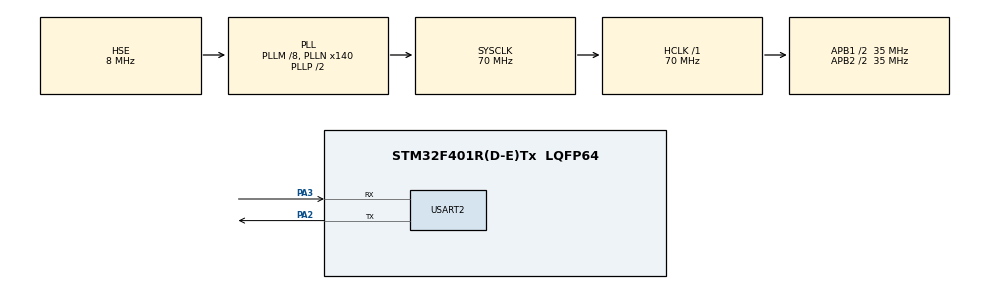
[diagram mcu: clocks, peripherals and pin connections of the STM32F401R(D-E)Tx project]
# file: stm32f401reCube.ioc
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Mcu.Family=STM32F4
Mcu.Name=STM32F401R(D-E)Tx
Mcu.Package=LQFP64
NVIC.PriorityGroup=NVIC_PRIORITYGROUP_4
NVIC.USART2_IRQn=true\:0\:0\:false\:false\:true\:true\:true
PA13.Mode=Serial_Wire
PA13.Signal=SYS_JTMS-SWDIO
PA14.Mode=Serial_Wire
PA14.Signal=SYS_JTCK-SWCLK
PA2.Mode=Asynchronous
PA2.Signal=USART2_TX
PA3.Mode=Asynchronous
PA3.Signal=USART2_RX
PH0\ -\ OSC_IN.Mode=HSE-External-Oscillator
PH0\ -\ OSC_IN.Signal=RCC_OSC_IN
PH1\ -\ OSC_OUT.Mode=HSE-External-Oscillator
PH1\ -\ OSC_OUT.Signal=RCC_OSC_OUT
ProjectManager.HeapSize=0x200
ProjectManager.StackSize=0x400
ProjectManager.TargetToolchain=STM32CubeIDE
RCC.48MHZClocksFreq_Value=35000000
RCC.AHBFreq_Value=70000000
RCC.APB1CLKDivider=RCC_HCLK_DIV2
RCC.APB1Freq_Value=35000000
RCC.APB1TimFreq_Value=70000000
RCC.APB2CLKDivider=RCC_HCLK_DIV2
RCC.APB2Freq_Value=35000000
RCC.APB2TimFreq_Value=70000000
RCC.CortexFreq_Value=70000000
RCC.HCLKFreq_Value=70000000
RCC.HSE_VALUE=8000000
RCC.HSI_VALUE=16000000
RCC.LSE_VALUE=32768
RCC.PLLN=140
RCC.SYSCLKFreq_VALUE=70000000
RCC.SYSCLKSource=RCC_SYSCLKSOURCE_PLLCLK
RCC.VCOOutputFreq_Value=140000000
USART2.VirtualMode=VM_ASYNC
board=custom

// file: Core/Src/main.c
/* USER CODE BEGIN Header */
/**
  ******************************************************************************
  * @file           : main.c
  * @brief          : Main program body
  ******************************************************************************
  * @attention
  *
  * <h2><center>&copy; Copyright (c) 2022 STMicroelectronics.
  * All rights reserved.</center></h2>
  *
  * This software component is licensed by ST under BSD 3-Clause license,
  * the "License"; You may not use this file except in compliance with the
  * License. You may obtain a copy of the License at:
  *                        opensource.org/licenses/BSD-3-Clause
  *
  ******************************************************************************
  */
/* USER CODE END Header */

#include "main.h"

UART_HandleTypeDef huart2;

void SystemClock_Config(void);
static void MX_GPIO_Init(void);
static void MX_USART2_UART_Init(void);

/* USER CODE BEGIN 0 */

//define main clock value
#define HCLK 70000000
//define System Tick Timer frequency
#define SysTicksClk 15000
//define System Tick Timer prescaler
#define SysTicks HCLK/SysTicksClk
uint32_t counter=0;
uint8_t RED_LED_PIN = 9;
uint8_t var=0;
uint8_t state = 0;

#define APB1_FREQ 35000000
#define BAUDRATE 115200

/*void SysTick_Handler(void)
{
	counter++;
	if(counter>=SysTicksClk){
		counter=0;
		if (var == 1){
			var = 0;
			GPIOC->ODR |= (1<<RED_LED_PIN);
		} else {
			var = 1;
			GPIOC->ODR &= ~(1<<RED_LED_PIN);
		}
	}

}

//void USART2_IRQHandler(void){
	//4.	Create a function - USART interrupts handler.

	//uint8_t read_char = USART2->DR;
	//const char c = 49;
	//const char b = 50;
/*
	if (read_char == 'E'){
		USART2->DR = c;
		state = 1;
	} else if (read_char == 'N'){
		USART2->DR = b;
	}*/
/*
	switch (read_char) {
	case 'N':
		if (state == 0){
			state = 1;
			USART2->DR = read_char;
		}
		break;
	case 'x':
		if (state == 1){
			state = 2 ;
			USART2->DR = read_char;
		}
		break;
	case '=':
		if (state == 2){
					state = 3 ;
					USART2->DR = read_char;
		}
		break;
	case 'E':
		if (state == 5){
					state = 0;
					USART2->DR = read_char;
		}
		break;

	default:
		if (state == 3){
			var = (uint8_t)read_char * 10;
			USART2->DR = read_char;
		} else if (state == 4){
			USART2->DR = read_char;
			var = var + (uint8_t)read_char;
			//USART2->DR = var;
		}
		break;
	}*/
	//NVIC_EnableIRQ(USART2_IRQn);
//}

/* USER CODE END 0 */

int main(void)
{

  /* MCU Configuration--------------------------------------------------------*/

  /* Reset of all peripherals, Initializes the Flash interface and the Systick. */
  HAL_Init();

  /* Configure the system clock */
  SystemClock_Config();

  /* Initialize all configured peripherals */
  MX_GPIO_Init();
  MX_USART2_UART_Init();
  /* USER CODE BEGIN 2 */
	//RCC->APB1ENR |= RCC_APB1ENR_USART2EN;

	//GPIOA->MODER |= 2 << GPIO_MODER_MODER2_Pos;
	//GPIOA->MODER |= 2 << GPIO_MODER_MODER3_Pos;

	//GPIOA->AFR[0] |= 7 << GPIO_AFRL_AFSEL2_Pos;
	//GPIOA->AFR[0] |= 7 << GPIO_AFRL_AFSEL3_Pos;

	// 1. Set USART2 baudrate
	//USART2->BRR = APB1_FREQ / BAUDRATE;
	/* 2. Configure USART to receive and
	* transmit data, generate the required
	* interrupt. */
	//USART2->CR1 |= USART_CR1_UE | USART_CR1_TE | USART_CR1_RE | USART_CR1_RXNEIE/* | USART_CR1_TXEIE*/;
	// 3. Enable interrupts in the interrupt controller.
	//NVIC_EnableIRQ(USART2_IRQn);
  /* USER CODE END 2 */

  /* Infinite loop */
  while (1)
  {

  }
}

void SystemClock_Config(void)
{
  RCC_OscInitTypeDef RCC_OscInitStruct = {0};
  RCC_ClkInitTypeDef RCC_ClkInitStruct = {0};

  /** Configure the main internal regulator output voltage
  */
  __HAL_RCC_PWR_CLK_ENABLE();
  __HAL_PWR_VOLTAGESCALING_CONFIG(PWR_REGULATOR_VOLTAGE_SCALE2);
  /** Initializes the CPU, AHB and APB busses clocks
  */
  RCC_OscInitStruct.OscillatorType = RCC_OSCILLATORTYPE_HSE;
  RCC_OscInitStruct.HSEState = RCC_HSE_ON;
  RCC_OscInitStruct.PLL.PLLState = RCC_PLL_ON;
  RCC_OscInitStruct.PLL.PLLSource = RCC_PLLSOURCE_HSE;
  RCC_OscInitStruct.PLL.PLLM = 8;
  RCC_OscInitStruct.PLL.PLLN = 140;
  RCC_OscInitStruct.PLL.PLLP = RCC_PLLP_DIV2;
  RCC_OscInitStruct.PLL.PLLQ = 4;
  if (HAL_RCC_OscConfig(&RCC_OscInitStruct) != HAL_OK)
  {
    Error_Handler();
  }
  /** Initializes the CPU, AHB and APB busses clocks
  */
  RCC_ClkInitStruct.ClockType = RCC_CLOCKTYPE_HCLK|RCC_CLOCKTYPE_SYSCLK
                              |RCC_CLOCKTYPE_PCLK1|RCC_CLOCKTYPE_PCLK2;
  RCC_ClkInitStruct.SYSCLKSource = RCC_SYSCLKSOURCE_PLLCLK;
  RCC_ClkInitStruct.AHBCLKDivider = RCC_SYSCLK_DIV1;
  RCC_ClkInitStruct.APB1CLKDivider = RCC_HCLK_DIV2;
  RCC_ClkInitStruct.APB2CLKDivider = RCC_HCLK_DIV2;

  if (HAL_RCC_ClockConfig(&RCC_ClkInitStruct, FLASH_LATENCY_2) != HAL_OK)
  {
    Error_Handler();
  }
}

static void MX_USART2_UART_Init(void)
{

  huart2.Instance = USART2;
  huart2.Init.BaudRate = 115200;
  huart2.Init.WordLength = UART_WORDLENGTH_8B;
  huart2.Init.StopBits = UART_STOPBITS_1;
  huart2.Init.Parity = UART_PARITY_NONE;
  huart2.Init.Mode = UART_MODE_TX_RX;
  huart2.Init.HwFlowCtl = UART_HWCONTROL_NONE;
  huart2.Init.OverSampling = UART_OVERSAMPLING_16;
  if (HAL_UART_Init(&huart2) != HAL_OK)
  {
    Error_Handler();
  }

}

static void MX_GPIO_Init(void)
{

  /* GPIO Ports Clock Enable */
  __HAL_RCC_GPIOH_CLK_ENABLE();
  __HAL_RCC_GPIOA_CLK_ENABLE();

}

void Error_Handler(void)
{
}

/************************ (C) COPYRIGHT STMicroelectronics *****END OF FILE****/
